# LPC865 register map
Vendor: nxp.com; File version: 1.0
CPU: CM0PLUS r0p0, little endian, no MPU, no FPU, VTOR, 2 interrupt priority bits
Registers are 32-bit, read-write, reset 0x0 unless marked. A register's access mark holds for its fields unless they carry their own. Offsets are from the block's base; [hi:lo] are bit positions; lines under a group give offsets from that group; {n}, {i} and the like mark numbered series; 'fields as' and 'values as' point back to an identical list.

## SYSCON — LPC84x System configuration (SYSCON)
Base 0x40048000
0x00 SYSMEMREMAP — System Remap register
  [1:0] MAP — System memory remap. Value 0x3 is reserved.
    0=BOOT_LOADER_MODE (Boot Loader Mode. Interrupt vectors are re-mapped to Boot ROM.); 1=USER_RAM_MODE (User RAM Mode. Interrupt vectors are re-mapped to Static RAM.); 2=USER_FLASH_MODE (User Flash Mode. Interrupt vectors are not re-mapped and reside in Flash.)
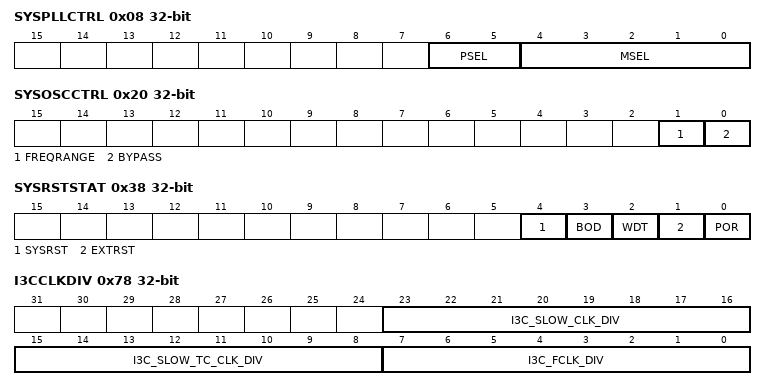
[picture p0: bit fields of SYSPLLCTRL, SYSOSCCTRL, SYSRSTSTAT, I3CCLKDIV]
0x08 SYSPLLCTRL — PLL control
  [6:5] PSEL — Post divider ratio P. The division ratio is 2 x P.
    0=P = 1; 1=P = 2; 2=P = 4; 3=P = 8
  [4:0] MSEL — Feedback divider value. The division value M is the programmed MSEL value + 1. 00000: Division ratio M = 1 to 11111: Division ratio M = 32
0x0C SYSPLLSTAT ro — PLL status
  [0] LOCK — PLL0 lock indicator
0x20 SYSOSCCTRL — system oscillator control
  [1] FREQRANGE — oscillator low / high transconductance selection input (Active High) 1-20MHz '0' : 15-50MHz '1'
  [0] BYPASS — oscillator (Xtal) Test Mode input (Active High)
0x28 FROOSCCTRL reset 0x8801 — FRO oscillator control
  [17] FRO_DIRECT — fro direct clock select
    0=DISABLED (fro_osc out is divided by 2 (normal boot)); 1=ENABLED (fro clock is direct from FRO oscillator)
0x30 FRODIRECTCLKUEN — FRO direct clock source update enable register
  [0] ENA — Enable fro clock source update
    0=NO_CHANGE; 1=UPDATED (update clock source)
0x38 SYSRSTSTAT — System reset status register
  [4] SYSRST — Status of the software system reset
    0=NO_DETECTED (No System reset detected); 1=DETECTED (System reset detected. Writing a one clears this reset.)
  [3] BOD — Status of the Brown-out detect reset
    0=NO_DETECTED (No BOD reset detected); 1=DETECTED (BOD reset detected. Writing a one clears this reset.)
  [2] WDT — Status of the Watchdog reset
    0=NO_DETECTED (No WDT reset detected); 1=DETECTED (WDT reset detected. Writing a one clears this reset.)
  [1] EXTRST — Status of the external RESET pin. External reset status.
    0=NO_DETECTED (No reset event detected.); 1=DETECTED (Reset detected. Writing a one clears this reset.)
  [0] POR — POR reset status
    0=NO_DETECTED (No POR detected); 1=DETECTED (POR detected. Writing a one clears this reset.)
0x40 SYSPLLCLKSEL — System PLL clock source select register
  [1:0] SEL — System PLL clock source
    0=FRO; 1=EXT_CLK (External clock); 2=LPOSC (Low power oscillator); 3=FRODIV
0x44 SYSPLLCLKUEN — System PLL clock source update enable register
  [0] ENA — Enable system PLL clock source update
    0=NO_CHANGE; 1=UPDATED (update clock source)
0x48 MAINCLKPLLSEL — Main clock source select register
  [1:0] SEL — System PLL clock source
    0=MAIN_CLK_PRE_PLL; 1=SYS_PLL; 2=none; 3=none
0x4C MAINCLKPLLUEN — Main clock source update enable register
  [0] ENA — Enable main clock source update
    0=NO_CHANGE; 1=UPDATED (update clock source)
0x50 MAINCLKSEL — Main clock source select register
  [1:0] SEL — System PLL clock source
    0=FRO; 1=EXT_CLK (External clock); 2=LPOSC (Low power oscillator); 3=FRO_DIV
0x54 MAINCLKUEN — Main clock source update enable register
  fields as MAINCLKPLLUEN
0x58 SYSAHBCLKDIV reset 0x1 — System clock divider register
  [7:0] DIV — System AHB clock divider values 0: System clock disabled. 1: Divide by 1. to 255: Divide by 255.
0x5C SYSPLLDIV reset 0x1 — System clock divider register
  [7:0] DIV — System PLL clock divider values 0: System PLL clock disabled. 1: Divide by 1. to 255: Divide by 255.
0x64 ADCCLKSEL — ADC clock source select register
  [1:0] SEL — Clock source for ADC clock
    0=FRO; 1=SYS_PLL; 2=NONE; 3=NONE1
0x68 ADCCLKDIV — ADC clock divider register
  [7:0] DIV — ADC clock divider values 0: ADC clock disabled. 1: Divide by 1. to 255: Divide by 255.
0x6C WKTCLKSEL — ADC clock source select register
  [0] SEL — WKT clock source selection
    0=FRO (FRO_INT); 1=SYS_PLL (LPOSC)
0x74 EXTCLKSEL — external clock source select register
  [0] SEL — Clock source for external clock
    0=SYS_OSC (System oscillator); 1=CLK_IN
0x78 I3CCLKDIV — I3C clock divider register
  [23:16] I3C_SLOW_CLK_DIV — i3c_slow_clk divider
  [15:8] I3C_SLOW_TC_CLK_DIV — i3c_slow_tc_clk clock divider
  [7:0] I3C_FCLK_DIV — i3c_fclk fast clock divider
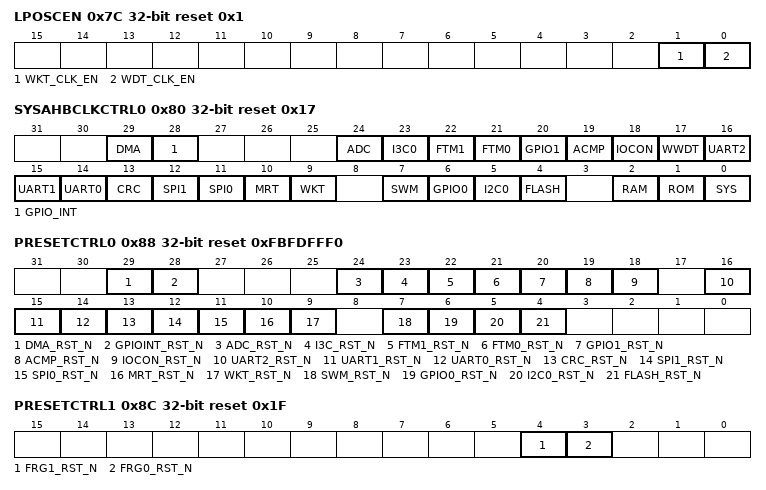
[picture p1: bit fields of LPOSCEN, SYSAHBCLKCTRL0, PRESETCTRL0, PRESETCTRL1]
0x7C LPOSCEN reset 0x1 — LPOSC enable register
  [1] WKT_CLK_EN — WDT count clock enable
    0=DISABLE; 1=ENABLE
  [0] WDT_CLK_EN — WDT count clock enable
    0=DISABLE; 1=ENABLE
0x80 SYSAHBCLKCTRL0 reset 0x17 — System clock group 0 control register
  [29] DMA — Enables clock for DMA.
    0=DISABLE; 1=ENABLE
  [28] GPIO_INT — Enable clock for GPIO pin interrupt registers
    0=DISABLE; 1=ENABLE
  [24] ADC — Enables clock for ADC.
    0=DISABLE; 1=ENABLE
  [23] I3C0 — Enables clock to I3C.
    0=DISABLE; 1=ENABLE
  [22] FTM1 — Enables clock for FTM1.
    0=DISABLE; 1=ENABLE
  [21] FTM0 — Enables clock for FTM0.
    0=DISABLE; 1=ENABLE
  [20] GPIO1 — Enables clock for GPIO1 port registers.
    0=DISABLE; 1=ENABLE
  [19] ACMP — Enables clock for analog comparator.
    0=DISABLE; 1=ENABLE
  [18] IOCON — Enables clock for IOCON.
    0=DISABLE; 1=ENABLE
  [17] WWDT — Enables clock for WWDT.
    0=DISABLE; 1=ENABLE
  [16] UART2 — Enables clock for UART2.
    0=DISABLE; 1=ENABLE
  [15] UART1 — Enables clock for UART1.
    0=DISABLE; 1=ENABLE
  [14] UART0 — Enables clock for UART0.
    0=DISABLE; 1=ENABLE
  [13] CRC — Enables clock for CRC.
    0=DISABLE; 1=ENABLE
  [12] SPI1 — Enables clock for SPI1.
    0=DISABLE; 1=ENABLE
  [11] SPI0 — Enables clock for SPI0.
    0=DISABLE; 1=ENABLE
  [10] MRT — Enables clock for multi-rate timer.
    0=DISABLE; 1=ENABLE
  [9] WKT — Enables clock for self-wake-up timer.
    0=DISABLE; 1=ENABLE
  [7] SWM — Enables clock for switch matrix.
    0=DISABLE; 1=ENABLE
  [6] GPIO0 — Enables clock for GPIO0 port registers.
    0=DISABLE; 1=ENABLE
  [5] I2C0 — Enables clock for I2C0.
    0=DISABLE; 1=ENABLE
  [4] FLASH — Enables clock for flash.
    0=DISABLE; 1=ENABLE
  [2] RAM — Enables clock for SRAM.
    0=DISABLE; 1=ENABLE
  [1] ROM — Enables clock for ROM.
    0=DISABLE; 1=ENABLE
  [0] SYS — Enables the clock for the AHB, the APB bridge, the Cortex-M0+ core clocks, SYSCON, and the PMU. This bit is read only and always reads as 1.
0x88 PRESETCTRL0 reset 0xFBFDFFF0 — Peripheral reset group 0 control register
  [29] DMA_RST_N — DMA reset control
    0=ASSERT (Assert the DMA reset.); 1=CLEAR (Clear the DMA reset.)
  [28] GPIOINT_RST_N — GPIOINT reset control
    0=ASSERT (Assert the GPIOINT reset.); 1=CLEAR (Clear the GPIOINT reset.)
  [24] ADC_RST_N — ADC reset control
    0=ASSERT (Assert the ADC reset.); 1=CLEAR (Clear the ADC reset.)
  [23] I3C_RST_N — I3C reset control
    0=ASSERT (Assert the I3C reset.); 1=CLEAR (Clear the I3C reset.)
  [22] FTM1_RST_N — FTM1 reset control
    0=ASSERT (Assert the FTM1 reset.); 1=CLEAR (Clear the FTM1 reset.)
  [21] FTM0_RST_N — FTM0 reset control
    0=ASSERT (Assert the FTM0 reset.); 1=CLEAR (Clear the FTM0 reset.)
  [20] GPIO1_RST_N — GPIO1 reset control
    0=ASSERT (Assert the GPIO1 reset.); 1=CLEAR (Clear the GPIO1 reset.)
  [19] ACMP_RST_N — Analog comparator reset control
    0=ASSERT (Assert the analog comparator reset.); 1=CLEAR (Clear the analog comparator reset.)
  [18] IOCON_RST_N — IOCON reset control
    0=ASSERT (Assert the IOCON reset.); 1=CLEAR (Clear the IOCON reset.)
  [16] UART2_RST_N — UART2 reset control
    0=ASSERT (Assert the UART2 reset.); 1=CLEAR (Clear the UART2 reset.)
  [15] UART1_RST_N — UART1 reset control
    0=ASSERT (Assert the UART1 reset.); 1=CLEAR (Clear the UART1 reset.)
  [14] UART0_RST_N — UART0 reset control
    0=ASSERT (Assert the UART0 reset.); 1=Clear the UART0 reset
  [13] CRC_RST_N — CRC engine reset control
    0=ASSERT (Assert the CRC reset.); 1=CLEAR (Clear the CRC reset.)
  [12] SPI1_RST_N — SPI1 reset control
    0=ASSERT (Assert the SPI1 reset.); 1=CLEAR (Clear the SPI1 reset.)
  [11] SPI0_RST_N — SPI0 reset control
    0=ASSERT (Assert the SPI0 reset.); 1=CLEAR (Clear the SPI0 reset.)
  [10] MRT_RST_N — Multi-rate timer (MRT) reset control
    0=ASSERT (Assert the MRT reset.); 1=CLEAR (Clear the MRT reset.)
  [9] WKT_RST_N — Self-wake-up timer (WKT) reset control
    0=ASSERT (Assert the WKT reset.); 1=CLEAR (Clear the WKT reset.)
  [7] SWM_RST_N — SWM reset control
    0=ASSERT (Assert the SWM reset.); 1=CLEAR (Clear the SWM reset.)
  [6] GPIO0_RST_N — GPIO0 reset control
    0=ASSERT (Assert the GPIO0 reset.); 1=CLEAR (Clear the GPIO0 reset.)
  [5] I2C0_RST_N — I2C0 reset control
    0=ASSERT (Assert the I2C0 reset.); 1=CLEAR (Clear the I2C0 reset.)
  [4] FLASH_RST_N — flash controller reset control
    0=ASSERT (Assert the flash controller reset.); 1=CLEAR (Clear the flash controller reset.)
0x8C PRESETCTRL1 reset 0x1F — Peripheral reset group 1 control register
  [4] FRG1_RST_N — Fractional baud rate generator 1 reset control
    0=ASSERT (Assert the FRG1 reset.); 1=CLEAR (Clear the FRG1 reset.)
  [3] FRG0_RST_N — Fractional baud rate generator 0 reset control
    0=ASSERT (Assert the FRG0 reset.); 1=CLEAR (Clear the FRG0 reset.)
{0x90+4i} FCLKSEL[{i}] (i=0..5) reset 0x7 — peripheral clock source select register. FCLK0SEL~FCLK2SEL are for UART0~UART2 clock source select register.FCLK3SEL~FCLK4SEL are reserved. FCLK5SEL is for I2C clock source select register.
  [2:0] SEL — Peripheral clock source
    0=FRO; 1=MAIN_CLK (main clock); 2=FRG0CLK; 3=FRG1CLK; 4=FRO_DIV; 5=NONE; 6=NONE1; 7=NONE2
0xA8 I3CCLKSEL reset 0x7 — I3C clock source select register
  [2:0] SEL — I3C clock source
    0=FRO; 1=EXT_CLK (external clock); 2=NONE; {v}=NONE{v-2} (v=3..7)
0xAC I3CSLOWTCCLKSEL reset 0x7 — I3CSLOWTC clock source select register
  [2:0] SEL — I3C clock source
    0=I3CFCLK; 1=LPOSC (Low power oscillator); 2=NONE; {v}=NONE{v-2} (v=3..7)
{0xB4+4i} FCLKSEL2[{i}] (i=0..1) reset 0x7 — peripheral clock source select register. FCLK0SEL2~FCLK2SEL2 are for SPI0~SPI1 clock source select register.
  fields as FCLKSEL[0]
0xBC FTM0INTTRIGDIV
  [6:0] FTM0_INT_TRIG_DIV — ftm0 ext_trigger_ftm0 or init_trigger_ftm0 divided by 1~128
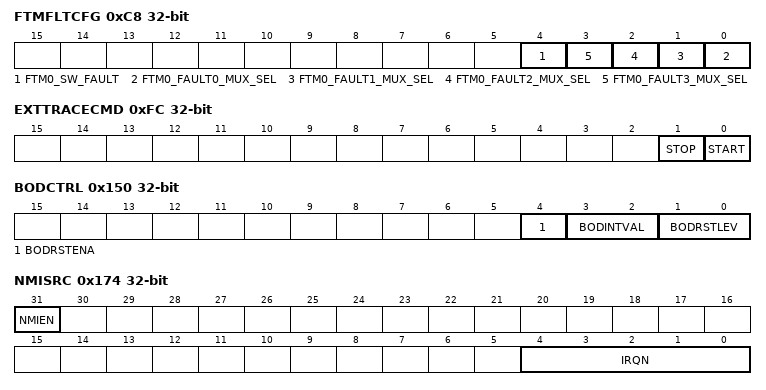
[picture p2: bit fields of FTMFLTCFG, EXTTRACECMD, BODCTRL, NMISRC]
0xC8 FTMFLTCFG — System clock divider register
  [4] FTM0_SW_FAULT — Software fault.
  [n] FTM0_FAULT{n}_MUX_SEL (n=0..3) — Mux selection FTM0 fault from external I/O or internal.
    0=EXTERNAL (Select external I/O); 1=INTERNAL (Select internal)
{0xD0+0x10*i} FRG[{i}] (i=0..1) group
  0x00 FRGDIV — fractional generator N divider value register
    [7:0] DIV — Denominator of the fractional divider. DIV is equal to the programmed value +1. Always set to 0xFF to use with the fractional baud rate generator.
  0x04 FRGMULT — fractional generator N multiplier value register
    [7:0] MULT — Numerator of the fractional divider. MULT is equal to the programmed value.
  0x08 FRGCLKSEL — FRG N clock source select register
    [1:0] SEL — Clock source for frgN_src clock
      0=FRO; 1=MAIN_CLK (main clock); 2=SYS_PLL; 3=NONE
0xF0 CLKOUTSEL — CLKOUT clock source select register
  [2:0] SEL — CLKOUT clock source
    0=FRO; 1=MAIN_CLK (main clock); 2=SYS_PLL; 3=EXT_CLK (external clock); 4=LPOSC (Low power oscillator); 5=NONE; 6=NONE1; 7=NONE2
0xF4 CLKOUTDIV — CLKOUT clock divider registers
  [7:0] DIV — CLKOUT clock divider values 0: Disable CLKOUT clock divider. 1: Divide by 1. to 255: Divide by 255.
0xFC EXTTRACECMD — External trace buffer command register
  [1] STOP — Trace stop command. Writing a one to this bit sets the TSTOP signal in the MTB to HIGH and stops tracing if the TSTOPEN bit in the MTB master register is set to one as well.
  [0] START — Trace start command. Writing a one to this bit sets the TSTART signal to the MTB to HIGH and starts tracing if the TSTARTEN bit in the MTB master register is set to one as well.
0x134 IOCONCLKDIV6 — Peripheral clock 6 to the IOCON block for programmable glitch filter
  [7:0] DIV — IOCON glitch filter clock divider values 0: Disable IOCONFILTR_PCLK. 1: Divide by 1. to 255: Divide by 255.
0x138 IOCONCLKDIV5 — Peripheral clock 6 to the IOCON block for programmable glitch filter
  fields as IOCONCLKDIV6
0x13C IOCONCLKDIV4 — Peripheral clock 4 to the IOCON block for programmable glitch filter
  fields as IOCONCLKDIV6
0x140 IOCONCLKDIV3 — Peripheral clock 3 to the IOCON block for programmable glitch filter
  fields as IOCONCLKDIV6
0x144 IOCONCLKDIV2 — Peripheral clock 2 to the IOCON block for programmable glitch filter
  fields as IOCONCLKDIV6
0x148 IOCONCLKDIV1 — Peripheral clock 1 to the IOCON block for programmable glitch filter
  fields as IOCONCLKDIV6
0x14C IOCONCLKDIV0 — Peripheral clock 0 to the IOCON block for programmable glitch filter
  fields as IOCONCLKDIV6
0x150 BODCTRL — BOD control register
  [4] BODRSTENA — BOD reset enable
    0=DISABLE (Disable reset function.); 1=ENABLE (Enable reset function.)
  [3:2] BODINTVAL — BOD interrupt level
    1=LEVEL_1; 2=LEVEL_2; 3=LEVEL_3
  [1:0] BODRSTLEV — BOD reset level
    1=LEVEL_1; 2=LEVEL_2; 3=LEVEL_3
0x154 SYSTCKCAL — System tick timer calibration register
  [25:0] CAL — System tick timer calibration value.
0x170 IRQLATENCY reset 0x10
  [7:0] LATENCY — 8-bit latency value.
0x174 NMISRC — NMI source selection register
  [31] NMIEN — Write a 1 to this bit to enable the Non-Maskable Interrupt (NMI) source selected by bits 4:0.
  [4:0] IRQN — The IRQ number of the interrupt that acts as the Non-Maskable Interrupt (NMI) if bit 31 is 1
{0x178+4i} PINTSEL[{i}] (i=0..7) — Pin interrupt select registers N
  [5:0] INTPIN — Pin number select for pin interrupt or pattern match engine input. (PIO0_0 to PIO0_31correspond to numbers 0 to 31 and PIO1_0 to PIO1_31 correspond to numbers 32 to 63).
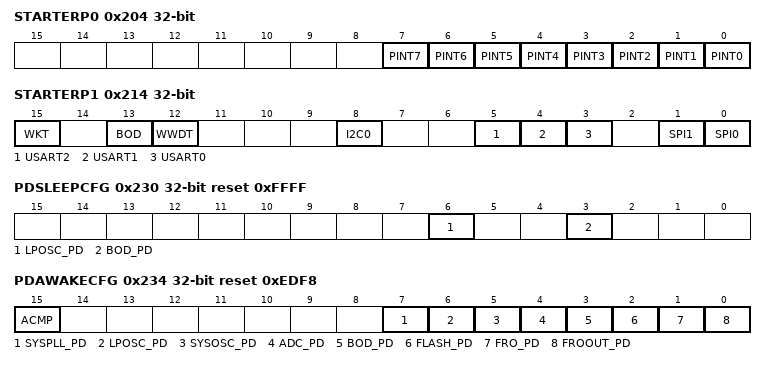
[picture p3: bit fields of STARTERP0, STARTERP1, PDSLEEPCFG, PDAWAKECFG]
0x204 STARTERP0 — Start logic 0 pin wake-up enable register 0
  [all] fields
    0=DISABLED; 1=ENABLED
  [n] PINT{n} (n=0..7) — GPIO pin interrupt {n} wake-up
0x214 STARTERP1 (reset mask 0xFF) — Start logic 0 pin wake-up enable register 1
  [all] fields
    0=DISABLED; 1=ENABLED
  [15] WKT — Self-wake-up timer interrupt wake-up
  [13] BOD — BOD interrupt wake-up
  [12] WWDT — WWDT interrupt wake-up
  [8] I2C0 — I2C0 interrupt wake-up.
  [5] USART2 — USART2 interrupt wake-up. Configure USART in synchronous slave mode.
  [4] USART1 — USART1 interrupt wake-up. Configure USART in synchronous slave mode.
  [3] USART0 — USART0 interrupt wake-up. Configure USART in synchronous slave mode.
  [1] SPI1 — SPI1 interrupt wake-up
  [0] SPI0 — SPI0 interrupt wake-up
0x230 PDSLEEPCFG reset 0xFFFF — Deep-sleep configuration register
  [6] LPOSC_PD — Low power oscillator power-down control for Deep-sleep and Power-down mode. Changing this bit to powered-down has no effect when the LOCK bit in the WWDT MOD register is set. In this case, the Low power oscillator is always running.
    0=DISABLED; 1=ENABLED
  [3] BOD_PD — BOD power-down control for Deep-sleep and Power-down mode
    0=POWERED; 1=POWERED_DOWN
0x234 PDAWAKECFG reset 0xEDF8 — Wake-up configuration register
  [15] ACMP — Analog comparator wake-up configuration
    0=DISABLED; 1=ENABLED
  [7] SYSPLL_PD — System PLL wake-up configuration
    0=DISABLED; 1=ENABLED
  [6] LPOSC_PD — Low power oscillator wake-up configuration. Changing this bit to powered-down has no effect when the LOCK bit in the WWDT MOD register is set. In this case, the Low power oscillator is always running
    0=DISABLED; 1=ENABLED
  [5] SYSOSC_PD — Crystal oscillator wake-up configuration
    0=POWERED; 1=POWERED_DOWN
  [4] ADC_PD — ADC wake-up configuration
    0=POWERED; 1=POWERED_DOWN
  [3] BOD_PD — BOD wake-up configuration
    0=POWERED; 1=POWERED_DOWN
  [2] FLASH_PD — Flash wake-up configuration
    0=POWERED; 1=POWERED_DOWN
  [1] FRO_PD — FRO oscillator power-down wake-up configuration
    0=POWERED; 1=POWERED_DOWN
  [0] FROOUT_PD — FRO oscillator output wake-up configuration
    0=POWERED; 1=POWERED_DOWN
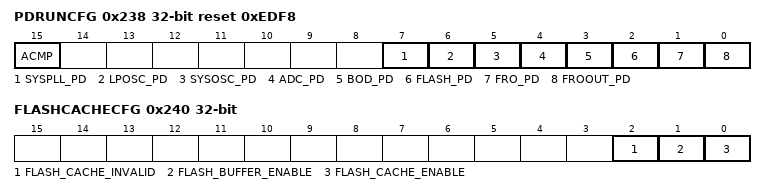
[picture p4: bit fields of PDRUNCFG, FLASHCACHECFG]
0x238 PDRUNCFG reset 0xEDF8 — Power configuration register
  fields as PDAWAKECFG
0x240 FLASHCACHECFG — Flash cache configuration register
  [all] fields
    0=DISABLE; 1=ENABLE
  [2] FLASH_CACHE_INVALID
  [1] FLASH_BUFFER_ENABLE
  [0] FLASH_CACHE_ENABLE
0x3F8 DEVICE_ID ro — Part ID register
  [31:0] DEVICEID — Part ID
